# cyw20829 register map
Vendor: Infineon Technologies; Series: CYW20829; File version: 1.0
CPU: CM33 r0p1, little endian, MPU, no FPU, VTOR, 3 interrupt priority bits
Registers are 32-bit, read-write, reset 0x0 unless marked. A register's access mark holds for its fields unless they carry their own. Offsets are from the block's base; [hi:lo] are bit positions.

## MXKEYSCAN — 0
Base 0x40920000
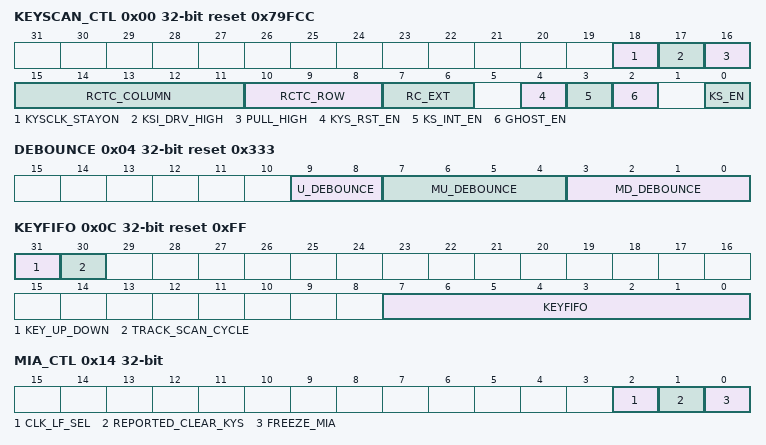
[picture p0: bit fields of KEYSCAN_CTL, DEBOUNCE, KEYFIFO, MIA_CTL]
0x00 KEYSCAN_CTL reset 0x79FCC — Keyscan Control Reg
  [18] KYSCLK_STAYON — the keyscan clock will stay on when set; otherwise, the clock will be gated off by when no activity is detected
  [17] KSI_DRV_HIGH — (THIS IS NOT USED and implemented in RTL) when in keyboard application this bit enables KSI rows to be outputs and driven high to accelerate the pull-up resistor effect for avoiding false key detection due to otherwise slow rising node
  [16] PULL_HIGH — used to pull the columns high after each column scan to alleviate slow rise-time due to a large key matrix capacitance;default is on.
  [15:11] RCTC_COLUMN — set the number of columns of the key matrx; program to one less than the number of column in the keyboard (default 19)
  [10:8] RCTC_ROW — set the number of rows of the key matrx; program to one less than the number of row in the keyboard.(default 7)
  [7:6] RC_EXT — Programmable idle duration between column scans. For example, rc_ext[1:0] = 1 will provide 1 clock cycle idle time of no column scan. This is to alleviate the problem of slow RC delay on some of the keyboard design. The valid values for rc_ext are 1, 2, and 3 (default)
  [4] KYS_RST_EN — Enable the reset of the debounce counters with kys_reported_clr bit; the reset clears the following registers: read/write counters for the event FIFO, debounce buffers, debouce counters, debouce up/down registers, cycle tracking registers and the keyscan read counter. For reset to take effect, the following two bits have to be set during clock unfreeze: this kys_rst_en and the 'reported_clear_kys' bit (note: ks_en can be at either states).
  [3] KS_INT_EN — This bit enables the keyscan block to wake the MCU module if key is detected.
  [2] GHOST_EN — Enable ghost detection
  [0] KS_EN — Enable the key scan module for keyboard function; specifically, the desired clock to the keyscan module is enabled.
0x04 DEBOUNCE reset 0x333 — Debounce (micro/macro)
  [9:8] U_DEBOUNCE — set the micro debounce count
  [7:4] MU_DEBOUNCE — macro up debounce count
  [3:0] MD_DEBOUNCE — macro down debounce count
0x08 KEYFIFO_CNT ro — Number of entries in Key FIFO
  [4:0] KEYFIFO_CNT — This register indicates the number of event that is ready for firmware access in the keycode event FIFO. Firmware to read this register before accessing the keycode event FIFO register. For example, a 1 on this register indicates that there is one event in the keycode event FIFO, so firmware can issue a read to the keycode event FIFO once. This number of key event is the accumulative key event count that is latched at the end of each hardware scan frame in a buffer register, it is then transferred to this event register when the 'freeze' is issued; its value is cleared when 'reported_clear_kys' bit is set in the mia_ctl_adr register. Note: Overflow condition (more than 20 keys detected in the scan cycle) may occur before the whole frame is scanned. If the 'overflow' bit is set and the keyfifo_cnt_adr register contains value that is less than 20, firmware needs to read this register a 2nd time. The balance of the event count will be automatically loaded into this register when the firmware issued 'reported_clear_kys' and 'unfreeze' if the hardware scan frame where overflow occurred has completed. However, perform a kys_rst_en maybe a better
0x0C KEYFIFO ro reset 0xFF — KEYFIFO values
  [31] KEY_UP_DOWN — indicator of key up (1) or down (0) for each key entry in the FIFO. Each of these bits are associated with the key code at bit[7:0].
  [30] TRACK_SCAN_CYCLE — a 1 or 0 value that indicates the hardware scan cycle that the key was detected; any key detected in the same hardware scan cycle will have the same track_cycle value. It toggles between 0 & 1 whenever a key in a scan cycle is detected; in other words, this value doesn't change when there is no key detected in the current scan cycle
  [7:0] KEYFIFO — contains detected key index; the event FIFO is 20-byte deep. After power up reset or soft reset defined by the 'kys_rst_en' bit, the event FIFO will contain 0xFF values.
0x14 MIA_CTL — MIA CTL (legacy)
  [2] CLK_LF_SEL — There is a potential bug when CLK_LF_SEL=1, based on the internals of the mxtk_clk_dividere used, and the output of the divider could be stuck. Please don't change this register unless there is a desperate need to debug the CLK_MF and switch over to only CLK_LF. ORIGINAL desicription: [Run the mxkeyscan internal processor at 32.786kHz, which will only work for small keypad sizes, and is an extreme way to lower power. Default is to use the 2MHz clk_mf source from the IMO]
  [1] REPORTED_CLEAR_KYS — After reading the MIA registers, firmware set this bit to instruct the MIA keyscan module to clear the keycode status, ghost status, & other internal registers. It is important that firmware clears and sets the bit properly (Read/write by uP). It is important to note that this bit only takes effect when the unfreeze occurs - it is a logical AND between this bit and the unfreeze that clears the registers. Therefore, it is advise that the firmware enters into any 'freeze operation' with the 'reported_clear_kys' bit cleared. (read/writable by uP, read only by MIA)
  [0] FREEZE_MIA — This bit when set will latch the accumulated key event count for firmware to access via the keyfifo_cnt_adr. After setting the freeze' bit, firmware needs to poll the 'clkrc_freezed' bit (synchronized to the 24MHz clock in hardware) in the 'mia_status_adr' register until it goes high, at which time read access to keyfifo_cnt & keyfifo_adr can proceed. After read access, firmware need to set this bit to low. The typical latency for freeze is 2.5 cycle of the 128KHz clock ~ 19.5us. Note: the clock in the keyscan module is not stopped when the freeze bit is set.
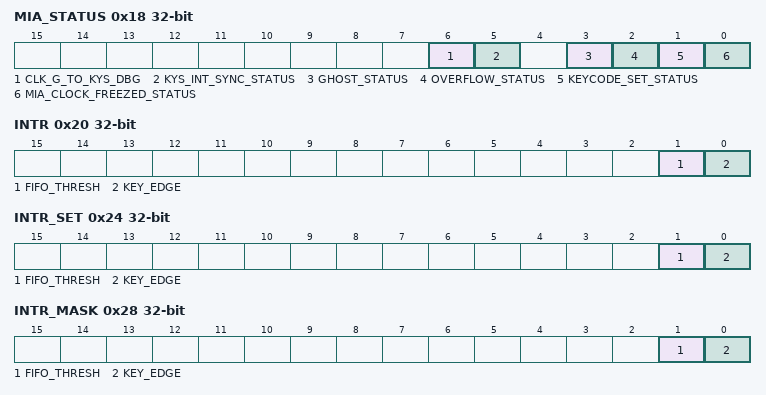
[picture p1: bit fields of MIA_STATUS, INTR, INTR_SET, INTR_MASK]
0x18 MIA_STATUS ro — MIA STAUS (Legacy)
  [6] CLK_G_TO_KYS_DBG — Debug status bit, poll this to see if the clock toggles and the divider is working. Double synced to clk_sys domain as an observe point also should help dft
  [5] KYS_INT_SYNC_STATUS — (Note: these bits can be read anytime, no need to freeze the MIA clock) kys_int_sync: status indicating that the keyscan interrupt is set. Refer to keyscan_ctl_adr for keyscan interruptenable - ks_int_en.
  [3] GHOST_STATUS — (Note: these bits can be read anytime, no need to freeze the MIA clock) Ghost: indicates the ghost keys are detected; 0xF5 is inserted in the event FIFO. Refer to keyscan_ctl_adr for ghost enable bit.
  [2] OVERFLOW_STATUS — (Note: these bits can be read anytime, no need to freeze the MIA clock) key FIFO overflow: The 20-byte key event FIFO overflows; more than 16 keys are pressed during current scan interval.
  [1] KEYCODE_SET_STATUS — (Note: these bits can be read anytime, no need to freeze the MIA clock) keycode_set indiates that the there is event in the key event FIFO.
  [0] MIA_CLOCK_FREEZED_STATUS — Firmware needs to poll this bit when trying to access/read the MIA registers. When this bit is high, the 'freeze' (bit 1 of the ksctl_adr register) is successful. Read access may proceed, otherwise, firmware has to wait and poll this bit until it is high. This bit is write by MIA and readable by the uP.
0x1C KSI_USED reset 0x7 — Number of input key rows
  [2:0] KSI_USED — define the number of row used for Keyscan; this definition is the same as that of the rctc register defined in MIA keyscan_ctl_adr[10:8]
0x20 INTR — Interrupt
  [1] FIFO_THRESH — HW sets this field to '1', when a INTERRUPT_FIFO_THRESH trigger is generated.
  [0] KEY_EDGE — HW sets this field to '1', when a INTERRUPT_KEY_EDGE trigger is generated.
0x24 INTR_SET — Interrupt set
  [1] FIFO_THRESH — Write this field with '1' to set corresponding INTR field (a write of '0' has no effect).
  [0] KEY_EDGE — Write this field with '1' to set corresponding INTR field (a write of '0' has no effect).
0x28 INTR_MASK — Interrupt mask
  [1] FIFO_THRESH — Mask for corresponding field in INTR register.
  [0] KEY_EDGE — Mask for corresponding field in INTR register.
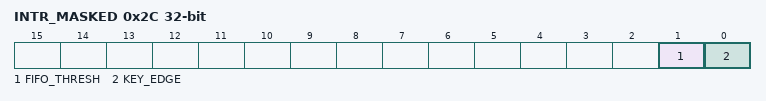
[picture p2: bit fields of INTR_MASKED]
0x2C INTR_MASKED ro — Interrupt mask
  [1] FIFO_THRESH — Logical AND of corresponding INTR and INTR_MASK fields.
  [0] KEY_EDGE — Logical AND of corresponding INTR and INTR_MASK fields.
